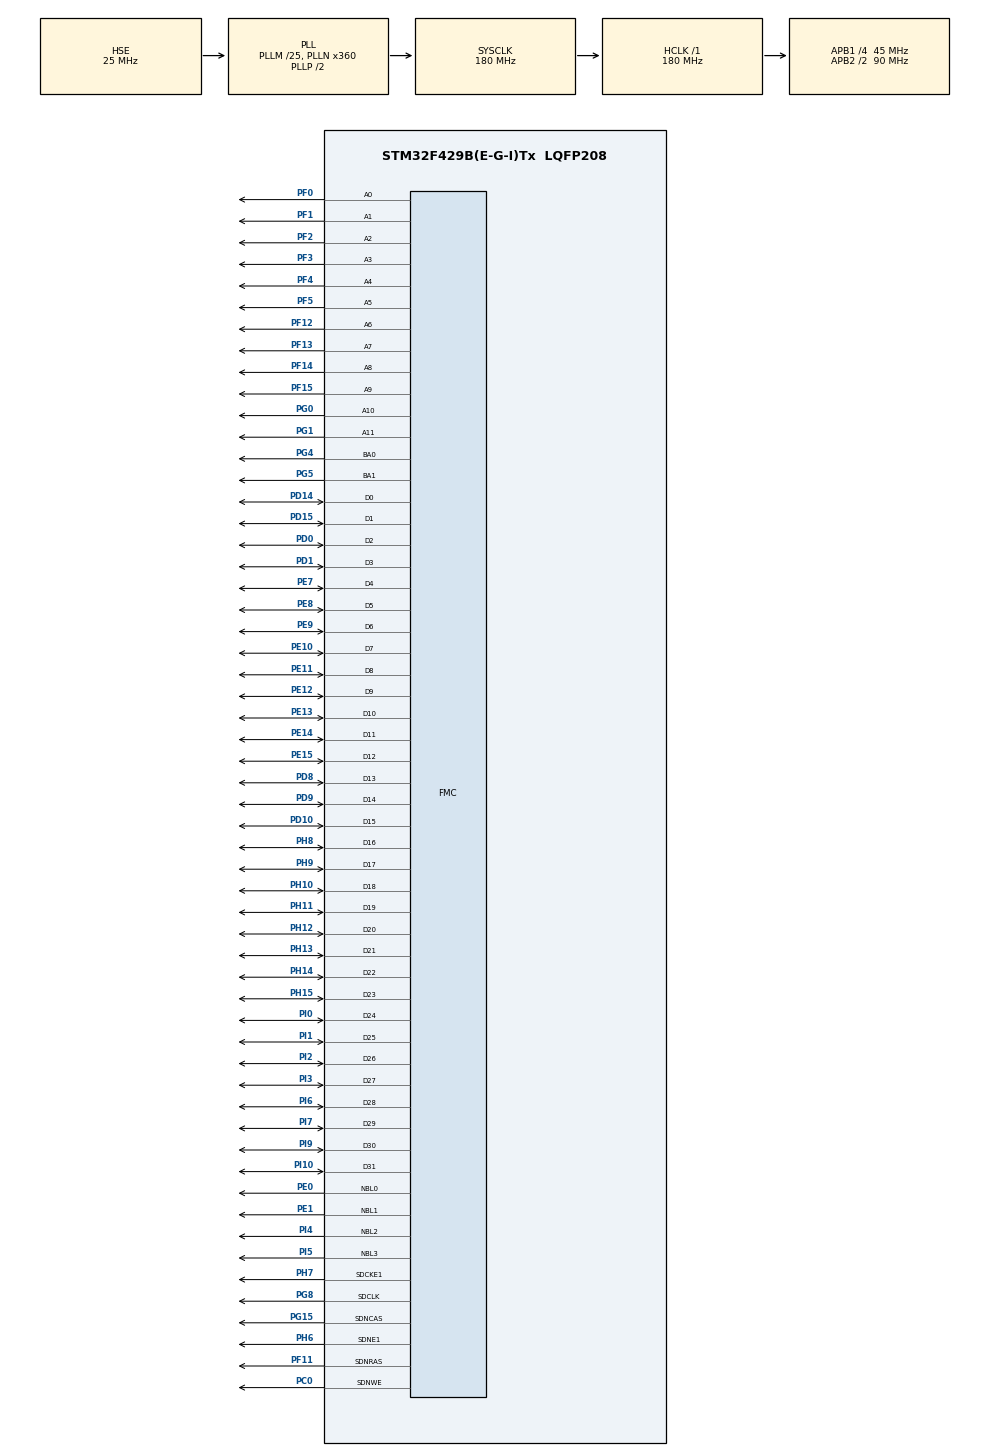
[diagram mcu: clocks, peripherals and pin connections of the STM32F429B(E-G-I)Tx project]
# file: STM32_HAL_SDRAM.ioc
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FMC.CASLatency2=FMC_SDRAM_CAS_LATENCY_3
FMC.ExitSelfRefreshDelay2=7
FMC.LoadToActiveDelay2=2
FMC.RCDDelay2=2
FMC.RPDelay1=2
FMC.RPDelay2=2
FMC.ReadBurst1=FMC_SDRAM_RBURST_ENABLE
FMC.ReadBurst2=FMC_SDRAM_RBURST_ENABLE
FMC.ReadPipeDelay1=FMC_SDRAM_RPIPE_DELAY_1
FMC.ReadPipeDelay2=FMC_SDRAM_RPIPE_DELAY_1
FMC.RowCycleDelay1=6
FMC.RowCycleDelay2=6
FMC.SDClockPeriod1=FMC_SDRAM_CLOCK_PERIOD_2
FMC.SDClockPeriod2=FMC_SDRAM_CLOCK_PERIOD_2
FMC.SelfRefreshTime2=5
FMC.WriteRecoveryTime2=3
Mcu.Family=STM32F4
Mcu.Name=STM32F429B(E-G-I)Tx
Mcu.Package=LQFP208
NVIC.PriorityGroup=NVIC_PRIORITYGROUP_4
PA13.Mode=Serial_Wire
PA13.Signal=SYS_JTMS-SWDIO
PA14.Mode=Serial_Wire
PA14.Signal=SYS_JTCK-SWCLK
PC0.Signal=FMC_SDNWE
PC14/OSC32_IN.Mode=LSE-External-Oscillator
PC14/OSC32_IN.Signal=RCC_OSC32_IN
PC15/OSC32_OUT.Mode=LSE-External-Oscillator
PC15/OSC32_OUT.Signal=RCC_OSC32_OUT
PD0.Signal=FMC_D2_DA2
PD1.Signal=FMC_D3_DA3
PD10.Signal=FMC_D15_DA15
PD14.Signal=FMC_D0_DA0
PD15.Signal=FMC_D1_DA1
PD8.Signal=FMC_D13_DA13
PD9.Signal=FMC_D14_DA14
PE0.Signal=FMC_NBL0
PE1.Signal=FMC_NBL1
PE10.Signal=FMC_D7_DA7
PE11.Signal=FMC_D8_DA8
PE12.Signal=FMC_D9_DA9
PE13.Signal=FMC_D10_DA10
PE14.Signal=FMC_D11_DA11
PE15.Signal=FMC_D12_DA12
PE7.Signal=FMC_D4_DA4
PE8.Signal=FMC_D5_DA5
PE9.Signal=FMC_D6_DA6
PF0.Signal=FMC_A0
PF1.Signal=FMC_A1
PF11.Signal=FMC_SDNRAS
PF12.Signal=FMC_A6
PF13.Signal=FMC_A7
PF14.Signal=FMC_A8
PF15.Signal=FMC_A9
PF2.Signal=FMC_A2
PF3.Signal=FMC_A3
PF4.Signal=FMC_A4
PF5.Signal=FMC_A5
PG0.Signal=FMC_A10
PG1.Signal=FMC_A11
PG15.Signal=FMC_SDNCAS
PG4.Signal=FMC_A14_BA0
PG5.Signal=FMC_A15_BA1
PG8.Signal=FMC_SDCLK
PH0/OSC_IN.Mode=HSE-External-Oscillator
PH0/OSC_IN.Signal=RCC_OSC_IN
PH1/OSC_OUT.Mode=HSE-External-Oscillator
PH1/OSC_OUT.Signal=RCC_OSC_OUT
PH10.Signal=FMC_D18
PH11.Signal=FMC_D19
PH12.Signal=FMC_D20
PH13.Signal=FMC_D21
PH14.Signal=FMC_D22
PH15.Signal=FMC_D23
PH6.Mode=SdramChipSelect2_2
PH6.Signal=FMC_SDNE1
PH7.Mode=SdramChipSelect2_2
PH7.Signal=FMC_SDCKE1
PH8.Signal=FMC_D16
PH9.Signal=FMC_D17
PI0.Signal=FMC_D24
PI1.Signal=FMC_D25
PI10.Signal=FMC_D31
PI2.Signal=FMC_D26
PI3.Signal=FMC_D27
PI4.Signal=FMC_NBL2
PI5.Signal=FMC_NBL3
PI6.Signal=FMC_D28
PI7.Signal=FMC_D29
PI9.Signal=FMC_D30
ProjectManager.HeapSize=0x200
ProjectManager.StackSize=0x400
ProjectManager.TargetToolchain=MDK-ARM V5
RCC.48MHZClocksFreq_Value=90000000
RCC.AHBFreq_Value=180000000
RCC.APB1CLKDivider=RCC_HCLK_DIV4
RCC.APB1Freq_Value=45000000
RCC.APB1TimFreq_Value=90000000
RCC.APB2CLKDivider=RCC_HCLK_DIV2
RCC.APB2Freq_Value=90000000
RCC.APB2TimFreq_Value=180000000
RCC.CortexFreq_Value=180000000
RCC.HCLKFreq_Value=180000000
RCC.HSE_VALUE=25000000
RCC.HSI_VALUE=16000000
RCC.PLLM=25
RCC.PLLN=360
RCC.PLLSourceVirtual=RCC_PLLSOURCE_HSE
RCC.SYSCLKFreq_VALUE=180000000
RCC.SYSCLKSource=RCC_SYSCLKSOURCE_PLLCLK
RCC.VCOOutputFreq_Value=360000000
SH.FMC_A0.0=FMC_A0,12b-sda2
SH.FMC_A1.0=FMC_A1,12b-sda2
SH.FMC_A10.0=FMC_A10,12b-sda2
SH.FMC_A11.0=FMC_A11,12b-sda2
SH.FMC_A14_BA0.0=FMC_BA0,FourSdramBanks2
SH.FMC_A15_BA1.0=FMC_BA1,FourSdramBanks2
SH.FMC_A2.0=FMC_A2,12b-sda2
SH.FMC_A3.0=FMC_A3,12b-sda2
SH.FMC_A4.0=FMC_A4,12b-sda2
SH.FMC_A5.0=FMC_A5,12b-sda2
SH.FMC_A6.0=FMC_A6,12b-sda2
SH.FMC_A7.0=FMC_A7,12b-sda2
SH.FMC_A8.0=FMC_A8,12b-sda2
SH.FMC_A9.0=FMC_A9,12b-sda2
SH.FMC_D0_DA0.0=FMC_D0,sd-32b-d2
SH.FMC_D10_DA10.0=FMC_D10,sd-32b-d2
SH.FMC_D11_DA11.0=FMC_D11,sd-32b-d2
SH.FMC_D12_DA12.0=FMC_D12,sd-32b-d2
SH.FMC_D13_DA13.0=FMC_D13,sd-32b-d2
SH.FMC_D14_DA14.0=FMC_D14,sd-32b-d2
SH.FMC_D15_DA15.0=FMC_D15,sd-32b-d2
SH.FMC_D16.0=FMC_D16,sd-32b-d2
SH.FMC_D17.0=FMC_D17,sd-32b-d2
SH.FMC_D18.0=FMC_D18,sd-32b-d2
SH.FMC_D19.0=FMC_D19,sd-32b-d2
SH.FMC_D1_DA1.0=FMC_D1,sd-32b-d2
SH.FMC_D20.0=FMC_D20,sd-32b-d2
SH.FMC_D21.0=FMC_D21,sd-32b-d2
SH.FMC_D22.0=FMC_D22,sd-32b-d2
SH.FMC_D23.0=FMC_D23,sd-32b-d2
SH.FMC_D24.0=FMC_D24,sd-32b-d2
SH.FMC_D25.0=FMC_D25,sd-32b-d2
SH.FMC_D26.0=FMC_D26,sd-32b-d2
SH.FMC_D27.0=FMC_D27,sd-32b-d2
SH.FMC_D28.0=FMC_D28,sd-32b-d2
SH.FMC_D29.0=FMC_D29,sd-32b-d2
SH.FMC_D2_DA2.0=FMC_D2,sd-32b-d2
SH.FMC_D30.0=FMC_D30,sd-32b-d2
SH.FMC_D31.0=FMC_D31,sd-32b-d2
SH.FMC_D3_DA3.0=FMC_D3,sd-32b-d2
SH.FMC_D4_DA4.0=FMC_D4,sd-32b-d2
SH.FMC_D5_DA5.0=FMC_D5,sd-32b-d2
SH.FMC_D6_DA6.0=FMC_D6,sd-32b-d2
SH.FMC_D7_DA7.0=FMC_D7,sd-32b-d2
SH.FMC_D8_DA8.0=FMC_D8,sd-32b-d2
SH.FMC_D9_DA9.0=FMC_D9,sd-32b-d2
SH.FMC_NBL0.0=FMC_NBL0,Sd4ByteEnable2
SH.FMC_NBL1.0=FMC_NBL1,Sd4ByteEnable2
SH.FMC_NBL2.0=FMC_NBL2,Sd4ByteEnable2
SH.FMC_NBL3.0=FMC_NBL3,Sd4ByteEnable2
SH.FMC_SDCLK.0=FMC_SDCLK,12b-sda2
SH.FMC_SDNCAS.0=FMC_SDNCAS,12b-sda2
SH.FMC_SDNRAS.0=FMC_SDNRAS,12b-sda2
SH.FMC_SDNWE.0=FMC_SDNWE,12b-sda2
board=custom

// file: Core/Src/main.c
/* USER CODE BEGIN Header */
/**
  ******************************************************************************
  * @file           : main.c
  * @brief          : Main program body
  ******************************************************************************
  * @attention
  *
  * <h2><center>&copy; Copyright (c) 2021 STMicroelectronics.
  * All rights reserved.</center></h2>
  *
  * This software component is licensed by ST under BSD 3-Clause license,
  * the "License"; You may not use this file except in compliance with the
  * License. You may obtain a copy of the License at:
  *                        opensource.org/licenses/BSD-3-Clause
  *
  ******************************************************************************
  */
/* USER CODE END Header */
#include "main.h"
#include "gpio.h"
#include "fmc.h"

void SystemClock_Config(void);

/* USER CODE BEGIN 0 */
uint32_t pbuff[(16*1024*1024)/4] __attribute__((at(0xD0000000)));
/* USER CODE END 0 */

int main(void)
{

  /* MCU Configuration--------------------------------------------------------*/

  /* Reset of all peripherals, Initializes the Flash interface and the Systick. */
  HAL_Init();

  /* Configure the system clock */
  SystemClock_Config();

  /* Initialize all configured peripherals */
  MX_GPIO_Init();
  MX_FMC_Init();
  /* USER CODE BEGIN 2 */
	for(int count=0;count<((16*1024*1024)/4);count++)
	  pbuff[count] = count;

	for(int count=0;count<((16*1024*1024)/4);count++)
	{
	  if(pbuff[count] != count)
			goto checkFailed;
	}
  /* USER CODE END 2 */

  /* Infinite loop */
  while (1)
  {

    /* USER CODE BEGIN 3 */
  }
checkFailed:
	while(1);
  /* USER CODE END 3 */
}

void SystemClock_Config(void)
{
  RCC_OscInitTypeDef RCC_OscInitStruct = {0};
  RCC_ClkInitTypeDef RCC_ClkInitStruct = {0};

  /** Configure the main internal regulator output voltage
  */
  __HAL_RCC_PWR_CLK_ENABLE();
  __HAL_PWR_VOLTAGESCALING_CONFIG(PWR_REGULATOR_VOLTAGE_SCALE1);
  /** Initializes the RCC Oscillators according to the specified parameters
  * in the RCC_OscInitTypeDef structure.
  */
  RCC_OscInitStruct.OscillatorType = RCC_OSCILLATORTYPE_HSE;
  RCC_OscInitStruct.HSEState = RCC_HSE_ON;
  RCC_OscInitStruct.PLL.PLLState = RCC_PLL_ON;
  RCC_OscInitStruct.PLL.PLLSource = RCC_PLLSOURCE_HSE;
  RCC_OscInitStruct.PLL.PLLM = 25;
  RCC_OscInitStruct.PLL.PLLN = 360;
  RCC_OscInitStruct.PLL.PLLP = RCC_PLLP_DIV2;
  RCC_OscInitStruct.PLL.PLLQ = 4;
  if (HAL_RCC_OscConfig(&RCC_OscInitStruct) != HAL_OK)
  {
    Error_Handler();
  }
  /** Activate the Over-Drive mode
  */
  if (HAL_PWREx_EnableOverDrive() != HAL_OK)
  {
    Error_Handler();
  }
  /** Initializes the CPU, AHB and APB buses clocks
  */
  RCC_ClkInitStruct.ClockType = RCC_CLOCKTYPE_HCLK|RCC_CLOCKTYPE_SYSCLK
                              |RCC_CLOCKTYPE_PCLK1|RCC_CLOCKTYPE_PCLK2;
  RCC_ClkInitStruct.SYSCLKSource = RCC_SYSCLKSOURCE_PLLCLK;
  RCC_ClkInitStruct.AHBCLKDivider = RCC_SYSCLK_DIV1;
  RCC_ClkInitStruct.APB1CLKDivider = RCC_HCLK_DIV4;
  RCC_ClkInitStruct.APB2CLKDivider = RCC_HCLK_DIV2;

  if (HAL_RCC_ClockConfig(&RCC_ClkInitStruct, FLASH_LATENCY_5) != HAL_OK)
  {
    Error_Handler();
  }
}

void Error_Handler(void)
{
  __disable_irq();
  while (1)
  {
  }
}

/************************ (C) COPYRIGHT STMicroelectronics *****END OF FILE****/
